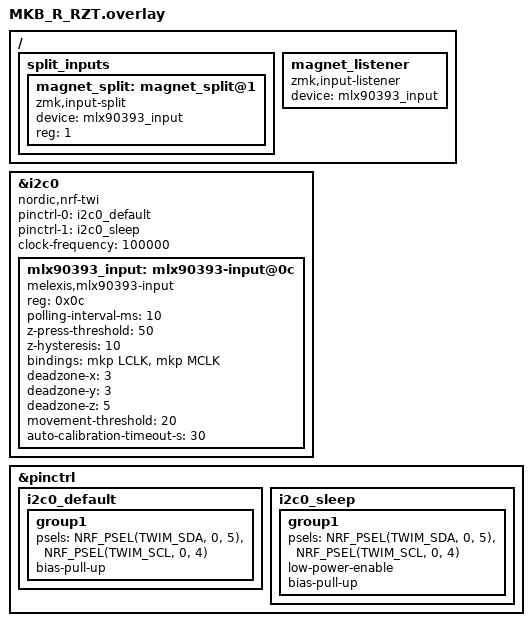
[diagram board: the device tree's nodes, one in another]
#include "MKB_R_Base.dtsi"
#include <dt-bindings/zmk/keys.h>
#include <dt-bindings/zmk/pointing.h>

&i2c0 {
    status = "okay";
    compatible = "nordic,nrf-twi";
    pinctrl-0 = <&i2c0_default>;
    pinctrl-1 = <&i2c0_sleep>;
    pinctrl-names = "default", "sleep";
    clock-frequency = <100000>; 
    
    mlx90393_input: mlx90393-input@0c {
        compatible = "melexis,mlx90393-input";
        reg = <0x0c>;
        
        polling-interval-ms = <10>;
        z-press-threshold = <50>;
        z-hysteresis = <10>;
        
        bindings = <&mkp LCLK>, <&mkp MCLK>;
        
        deadzone-x = <3>;
        deadzone-y = <3>;
        deadzone-z = <5>;
        
        movement-threshold = <20>;
        auto-calibration-timeout-s = <30>;
    };
};

&pinctrl {    
    i2c0_default: i2c0_default {
        group1 {
            psels = <NRF_PSEL(TWIM_SDA, 0,  5)>,
                    <NRF_PSEL(TWIM_SCL, 0,  4)>;
            bias-pull-up;
        };
    };
      
    i2c0_sleep: i2c0_sleep {
        group1 {
            psels = <NRF_PSEL(TWIM_SDA, 0,  5)>,
                    <NRF_PSEL(TWIM_SCL, 0,  4)>;
            low-power-enable;
            bias-pull-up;
        };
    };
};

/*input-split*/
/ {
    split_inputs {
        #address-cells = <1>;
        #size-cells = <0>;

        magnet_split: magnet_split@1 {
            compatible = "zmk,input-split";
            status = "okay";
            device = <&mlx90393_input>;
            reg = <1>;
        };
    };

    magnet_listener: magnet_listener {
        compatible = "zmk,input-listener";
        status = "okay";
        device = <&mlx90393_input>;
    };
};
